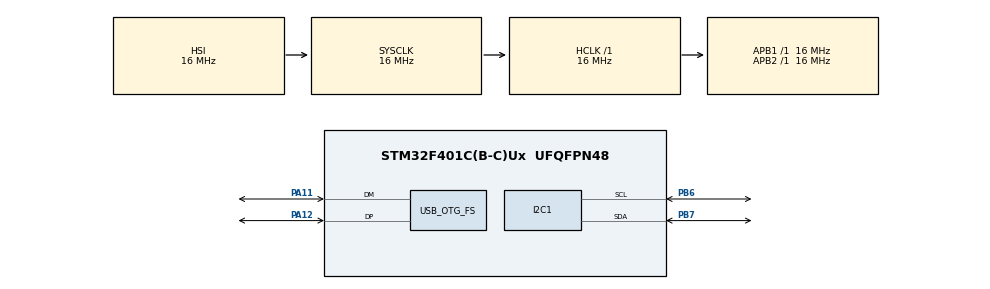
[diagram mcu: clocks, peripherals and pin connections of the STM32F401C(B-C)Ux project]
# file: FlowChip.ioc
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IWDG.Prescaler=IWDG_PRESCALER_128
IWDG.Reload=500
Mcu.Family=STM32F4
Mcu.Name=STM32F401C(B-C)Ux
Mcu.Package=UFQFPN48
NVIC.OTG_FS_IRQn=true\:0\:0\:false\:false\:true\:false\:true\:true
NVIC.PriorityGroup=NVIC_PRIORITYGROUP_4
PA11.Mode=Device_Only
PA11.Signal=USB_OTG_FS_DM
PA12.Mode=Device_Only
PA12.Signal=USB_OTG_FS_DP
PB6.GPIO_Pu=GPIO_PULLUP
PB6.Mode=I2C
PB6.Signal=I2C1_SCL
PB7.GPIO_Pu=GPIO_PULLUP
PB7.Mode=I2C
PB7.Signal=I2C1_SDA
PH0\ -\ OSC_IN.Mode=HSE-External-Oscillator
PH0\ -\ OSC_IN.Signal=RCC_OSC_IN
PH1\ -\ OSC_OUT.Mode=HSE-External-Oscillator
PH1\ -\ OSC_OUT.Signal=RCC_OSC_OUT
ProjectManager.HeapSize=0x600
ProjectManager.StackSize=0x400
ProjectManager.TargetToolchain=Makefile
RCC.48MHZClocksFreq_Value=48000000
RCC.AHBFreq_Value=16000000
RCC.APB1Freq_Value=16000000
RCC.APB2Freq_Value=16000000
RCC.CortexFreq_Value=16000000
RCC.HSE_VALUE=16000000
RCC.HSI_VALUE=16000000
RCC.LSE_VALUE=32768
RCC.PLLM=8
RCC.PLLN=72
RCC.PLLQ=3
RCC.SYSCLKFreq_VALUE=16000000
RCC.VCOOutputFreq_Value=144000000
USB_DEVICE.CLASS_NAME_FS=CDC
USB_DEVICE.VirtualMode=Cdc
USB_DEVICE.VirtualModeFS=Cdc_FS
USB_OTG_FS.VirtualMode=Device_Only
VP_CRC_VS_CRC.Mode=CRC_Activate
VP_IWDG_VS_IWDG.Mode=IWDG_Activate
VP_TIM1_VS_ClockSourceINT.Mode=Internal
VP_USB_DEVICE_VS_USB_DEVICE_CDC_FS.Mode=CDC_FS
VP_WWDG_VS_WWDG.Mode=WWDG_Activate
WWDG.Counter=127
WWDG.Prescaler=WWDG_PRESCALER_8
WWDG.Window=127
board=custom

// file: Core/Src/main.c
/* USER CODE BEGIN Header */
/**
 ******************************************************************************
 * @file           : main.c
 * @brief          : Main program body
 ******************************************************************************
 * @attention
 *
 * <h2><center>&copy; Copyright (c) 2021 STMicroelectronics.
 * All rights reserved.</center></h2>
 *
 * This software component is licensed by ST under Ultimate Liberty license
 * SLA0044, the "License"; You may not use this file except in compliance with
 * the License. You may obtain a copy of the License at:
 *                             www.st.com/SLA0044
 *
 ******************************************************************************
 */
/* USER CODE END Header */
#include "main.h"
#include "usb_device.h"

/* USER CODE BEGIN Includes */
#include "CAProtocolStm.h"
#include "flowChip.h"

/* USER CODE END Includes */

CRC_HandleTypeDef hcrc;

I2C_HandleTypeDef hi2c1;

IWDG_HandleTypeDef hiwdg;

TIM_HandleTypeDef htim1;

WWDG_HandleTypeDef hwwdg;

void SystemClock_Config(void);
static void MX_GPIO_Init(void);
static void MX_I2C1_Init(void);
static void MX_TIM1_Init(void);
static void MX_WWDG_Init(void);
static void MX_CRC_Init(void);
static void MX_IWDG_Init(void);

int main(void)
{

  /* MCU Configuration--------------------------------------------------------*/

  /* Reset of all peripherals, Initializes the Flash interface and the Systick. */
  HAL_Init();

  /* Configure the system clock */
  SystemClock_Config();

  /* USER CODE BEGIN SysInit */
  const char* bootMsg = CAonBoot();
  /* USER CODE END SysInit */

  /* Initialize all configured peripherals */
  MX_GPIO_Init();
  MX_I2C1_Init();
  MX_USB_DEVICE_Init();
  MX_TIM1_Init();
  MX_WWDG_Init();
  MX_CRC_Init();
  MX_IWDG_Init();
  /* USER CODE BEGIN 2 */
  flowChipInit(&hi2c1, &hwwdg, &hcrc);

  /* USER CODE END 2 */

  /* Infinite loop */
  /* USER CODE BEGIN WHILE */
  while (1) {
      HAL_IWDG_Refresh(&hiwdg);
      HAL_WWDG_Refresh(&hwwdg);
      flowChipLoop(bootMsg);
    /* USER CODE END WHILE */

  }
}

void SystemClock_Config(void)
{
  RCC_OscInitTypeDef RCC_OscInitStruct = {0};
  RCC_ClkInitTypeDef RCC_ClkInitStruct = {0};

  /** Configure the main internal regulator output voltage
  */
  __HAL_RCC_PWR_CLK_ENABLE();
  __HAL_PWR_VOLTAGESCALING_CONFIG(PWR_REGULATOR_VOLTAGE_SCALE2);

  /** Initializes the RCC Oscillators according to the specified parameters
  * in the RCC_OscInitTypeDef structure.
  */
  RCC_OscInitStruct.OscillatorType = RCC_OSCILLATORTYPE_HSI|RCC_OSCILLATORTYPE_LSI
                              |RCC_OSCILLATORTYPE_HSE;
  RCC_OscInitStruct.HSEState = RCC_HSE_ON;
  RCC_OscInitStruct.HSIState = RCC_HSI_ON;
  RCC_OscInitStruct.HSICalibrationValue = RCC_HSICALIBRATION_DEFAULT;
  RCC_OscInitStruct.LSIState = RCC_LSI_ON;
  RCC_OscInitStruct.PLL.PLLState = RCC_PLL_ON;
  RCC_OscInitStruct.PLL.PLLSource = RCC_PLLSOURCE_HSE;
  RCC_OscInitStruct.PLL.PLLM = 8;
  RCC_OscInitStruct.PLL.PLLN = 72;
  RCC_OscInitStruct.PLL.PLLP = RCC_PLLP_DIV2;
  RCC_OscInitStruct.PLL.PLLQ = 3;
  if (HAL_RCC_OscConfig(&RCC_OscInitStruct) != HAL_OK)
  {
    Error_Handler();
  }

  /** Initializes the CPU, AHB and APB buses clocks
  */
  RCC_ClkInitStruct.ClockType = RCC_CLOCKTYPE_HCLK|RCC_CLOCKTYPE_SYSCLK
                              |RCC_CLOCKTYPE_PCLK1|RCC_CLOCKTYPE_PCLK2;
  RCC_ClkInitStruct.SYSCLKSource = RCC_SYSCLKSOURCE_HSI;
  RCC_ClkInitStruct.AHBCLKDivider = RCC_SYSCLK_DIV1;
  RCC_ClkInitStruct.APB1CLKDivider = RCC_HCLK_DIV1;
  RCC_ClkInitStruct.APB2CLKDivider = RCC_HCLK_DIV1;

  if (HAL_RCC_ClockConfig(&RCC_ClkInitStruct, FLASH_LATENCY_0) != HAL_OK)
  {
    Error_Handler();
  }
}

static void MX_CRC_Init(void)
{

  hcrc.Instance = CRC;
  if (HAL_CRC_Init(&hcrc) != HAL_OK)
  {
    Error_Handler();
  }

}

static void MX_I2C1_Init(void)
{

  hi2c1.Instance = I2C1;
  hi2c1.Init.ClockSpeed = 100000;
  hi2c1.Init.DutyCycle = I2C_DUTYCYCLE_2;
  hi2c1.Init.OwnAddress1 = 0;
  hi2c1.Init.AddressingMode = I2C_ADDRESSINGMODE_7BIT;
  hi2c1.Init.DualAddressMode = I2C_DUALADDRESS_DISABLE;
  hi2c1.Init.OwnAddress2 = 0;
  hi2c1.Init.GeneralCallMode = I2C_GENERALCALL_DISABLE;
  hi2c1.Init.NoStretchMode = I2C_NOSTRETCH_DISABLE;
  if (HAL_I2C_Init(&hi2c1) != HAL_OK)
  {
    Error_Handler();
  }

}

static void MX_IWDG_Init(void)
{

  hiwdg.Instance = IWDG;
  hiwdg.Init.Prescaler = IWDG_PRESCALER_128;
  hiwdg.Init.Reload = 500;
  if (HAL_IWDG_Init(&hiwdg) != HAL_OK)
  {
    Error_Handler();
  }

}

static void MX_TIM1_Init(void)
{

  TIM_ClockConfigTypeDef sClockSourceConfig = {0};
  TIM_MasterConfigTypeDef sMasterConfig = {0};

  htim1.Instance = TIM1;
  htim1.Init.Prescaler = 0;
  htim1.Init.CounterMode = TIM_COUNTERMODE_UP;
  htim1.Init.Period = 65535;
  htim1.Init.ClockDivision = TIM_CLOCKDIVISION_DIV1;
  htim1.Init.RepetitionCounter = 0;
  htim1.Init.AutoReloadPreload = TIM_AUTORELOAD_PRELOAD_DISABLE;
  if (HAL_TIM_Base_Init(&htim1) != HAL_OK)
  {
    Error_Handler();
  }
  sClockSourceConfig.ClockSource = TIM_CLOCKSOURCE_INTERNAL;
  if (HAL_TIM_ConfigClockSource(&htim1, &sClockSourceConfig) != HAL_OK)
  {
    Error_Handler();
  }
  sMasterConfig.MasterOutputTrigger = TIM_TRGO_RESET;
  sMasterConfig.MasterSlaveMode = TIM_MASTERSLAVEMODE_DISABLE;
  if (HAL_TIMEx_MasterConfigSynchronization(&htim1, &sMasterConfig) != HAL_OK)
  {
    Error_Handler();
  }

}

static void MX_WWDG_Init(void)
{

  hwwdg.Instance = WWDG;
  hwwdg.Init.Prescaler = WWDG_PRESCALER_8;
  hwwdg.Init.Window = 127;
  hwwdg.Init.Counter = 127;
  hwwdg.Init.EWIMode = WWDG_EWI_DISABLE;
  if (HAL_WWDG_Init(&hwwdg) != HAL_OK)
  {
    Error_Handler();
  }

}

static void MX_GPIO_Init(void)
{

  /* GPIO Ports Clock Enable */
  __HAL_RCC_GPIOH_CLK_ENABLE();
  __HAL_RCC_GPIOA_CLK_ENABLE();
  __HAL_RCC_GPIOB_CLK_ENABLE();

}

void Error_Handler(void)
{
  __disable_irq();
  while (1) {
  }
}
